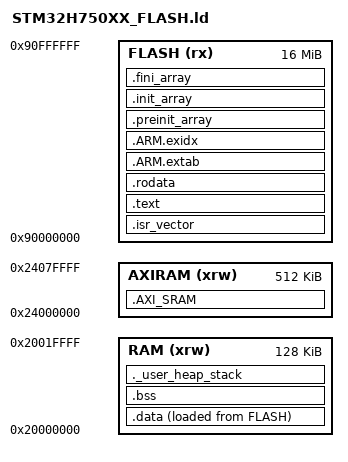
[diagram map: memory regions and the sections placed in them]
/* Screen application runs from QSPI at 0x90000000 through the existing BOOT.
 * Address matches SystemInit VTOR, supplied application HEX and programmer config.
 * DMA buffers use AXI SRAM; startup data/BSS and stack use internal DTCM. */
ENTRY(Reset_Handler)
MEMORY
{
  FLASH (rx) : ORIGIN = 0x90000000, LENGTH = 16M
  RAM (xrw) : ORIGIN = 0x20000000, LENGTH = 128K
  AXIRAM (xrw) : ORIGIN = 0x24000000, LENGTH = 512K
}
_estack = ORIGIN(RAM) + LENGTH(RAM);
_Min_Heap_Size = 0x400;
_Min_Stack_Size = 0x4000;
SECTIONS
{
  .isr_vector : { . = ALIGN(4); KEEP(*(.isr_vector)) . = ALIGN(4); } > FLASH
  .text : { . = ALIGN(4); *(.text) *(.text*) *(.glue_7) *(.glue_7t) KEEP(*(.init)) KEEP(*(.fini)) . = ALIGN(4); _etext = .; } > FLASH
  .rodata : { . = ALIGN(4); *(.rodata) *(.rodata*) . = ALIGN(4); } > FLASH
  .ARM.extab : { *(.ARM.extab* .gnu.linkonce.armextab.*) } > FLASH
  .ARM.exidx : { __exidx_start = .; *(.ARM.exidx*) __exidx_end = .; } > FLASH
  .preinit_array : { PROVIDE_HIDDEN(__preinit_array_start = .); KEEP(*(.preinit_array*)) PROVIDE_HIDDEN(__preinit_array_end = .); } > FLASH
  .init_array : { PROVIDE_HIDDEN(__init_array_start = .); KEEP(*(SORT(.init_array.*))) KEEP(*(.init_array*)) PROVIDE_HIDDEN(__init_array_end = .); } > FLASH
  .fini_array : { PROVIDE_HIDDEN(__fini_array_start = .); KEEP(*(SORT(.fini_array.*))) KEEP(*(.fini_array*)) PROVIDE_HIDDEN(__fini_array_end = .); } > FLASH
  _sidata = LOADADDR(.data);
  .data : { . = ALIGN(4); _sdata = .; *(.data) *(.data*) . = ALIGN(4); _edata = .; } > RAM AT > FLASH
  .bss (NOLOAD) : { . = ALIGN(4); _sbss = .; __bss_start__ = .; *(.bss) *(.bss*) *(COMMON) . = ALIGN(4); _ebss = .; __bss_end__ = .; } > RAM
  .AXI_SRAM (NOLOAD) : { . = ALIGN(32); *(.AXI_SRAM) *(.AXI_SRAM*) . = ALIGN(32); } > AXIRAM
  ._user_heap_stack (NOLOAD) : { . = ALIGN(8); PROVIDE(end = .); PROVIDE(_end = .); . = . + _Min_Heap_Size; . = . + _Min_Stack_Size; . = ALIGN(8); } > RAM
  .ARM.attributes 0 : { *(.ARM.attributes) }
}
